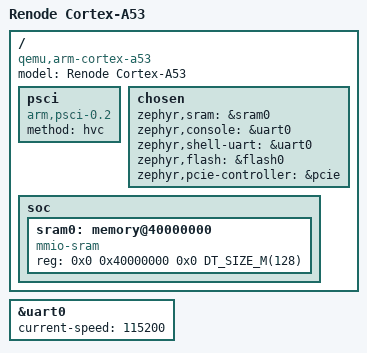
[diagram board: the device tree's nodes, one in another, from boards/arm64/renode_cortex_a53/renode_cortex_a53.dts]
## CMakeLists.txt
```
# Copyright (c) 2024 Google LLC
# SPDX-License-Identifier: Apache-2.0

cmake_minimum_required(VERSION 3.20)
find_package(Zephyr REQUIRED HINTS $ENV{ZEPHYR_BASE})

project(zephyr-pigweed LANGUAGES C CXX)

if(NOT CONFIG_TEST)
  target_sources(app PRIVATE src/main.cc)
else()
  target_sources(app PRIVATE src/test_main.cc)
  target_link_libraries(app
    PRIVATE
      hello_world.test.lib
      pw_unit_test.light
      pw_unit_test.logging_event_handler
  )
endif()

target_link_libraries(app PRIVATE hello_world)
```

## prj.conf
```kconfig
# Copyright (c) 2024 Google LLC
# SPDX-License-Identifier: Apache-2.0

# C++ configs
CONFIG_CPP=y
CONFIG_STD_CPP17=y
CONFIG_REQUIRES_FULL_LIBCPP=y

# Logging
CONFIG_LOG=y
CONFIG_PIGWEED_THREAD_SLEEP=y
#CONFIG_PIGWEED_LOG_TOKENIZED=y
```

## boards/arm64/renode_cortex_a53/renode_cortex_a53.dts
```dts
/dts-v1/;
#include <arm64/qemu/qemu-virt-a53.dtsi>

/ {
	model = "Renode Cortex-A53";
	compatible = "qemu,arm-cortex-a53";

	psci {
		compatible = "arm,psci-0.2";
		method = "hvc";
	};

	chosen {
		zephyr,sram = &sram0;
		zephyr,console = &uart0;
		zephyr,shell-uart = &uart0;
		zephyr,flash = &flash0;
		zephyr,pcie-controller = &pcie;
	};

	soc {
		sram0: memory@40000000 {
			compatible = "mmio-sram";
			reg = <0x0 0x40000000 0x0 DT_SIZE_M(128)>;
		};

	};
};

&uart0 {
	status = "okay";
	current-speed = <115200>;
};
```

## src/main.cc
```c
/* Copyright (c) 2024 Google LLC
 * SPDX-License-Identifier: Apache-2.0
 */

#define PW_LOG_MODULE_NAME "codelab"

#include "hello.h"
#include "pw_log/log.h"

int main() {
  pw::StringBuffer<128> buffer;
  pw::InlineString<6> greeting = "Hello";
  pw::InlineString<6> name = "World";
  app::WelcomeMessage(buffer, greeting, name);
  PW_LOG_INFO("%s", buffer.c_str());
  return 0;
}
```

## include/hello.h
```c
//
// Created by peress on 05/01/24.
//

#pragma once

#include "pw_string/string_builder.h"

namespace app {

void WelcomeMessage(pw::StringBuilder &buffer, const std::string_view board,
                    const std::string_view bin_name);

} // namespace app
```

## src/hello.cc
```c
#include "hello.h"

namespace app {

void WelcomeMessage(pw::StringBuilder &buffer, const std::string_view board,
                    const std::string_view bin_name) {
  buffer << board << " / " << bin_name << ".exe";
}

}  // namespace app
```

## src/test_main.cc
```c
/* Copyright (c) 2024 Google LLC
 * SPDX-License-Identifier: Apache-2.0
 */

#include "pw_unit_test/framework.h"
#include "pw_unit_test/logging_event_handler.h"

int main(int argc, char** argv) {
  testing::InitGoogleTest(&argc, argv);
  pw::unit_test::LoggingEventHandler handler;
  pw::unit_test::RegisterEventHandler(&handler);
  return RUN_ALL_TESTS();
}
```
